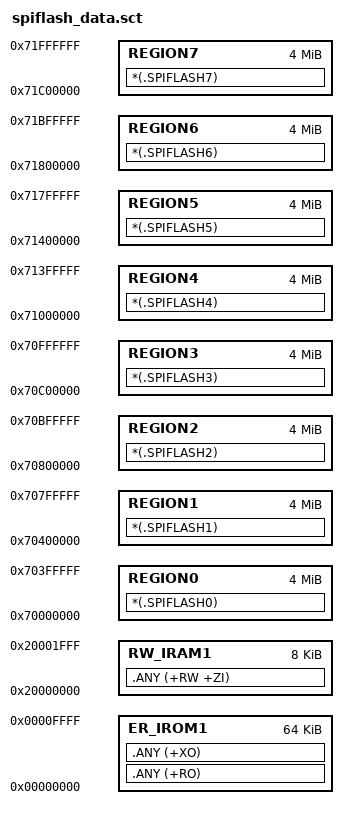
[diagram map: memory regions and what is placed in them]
; *************************************************************
; *** Scatter-Loading Description File generated by uVision ***
; *************************************************************
LR_IROM1 0x00000000 0x00010000  {    ; load region size_region
  ER_IROM1 0x00000000 0x00010000  {  ; load address = execution address
   .ANY (+RO)
   .ANY (+XO)
  }
  RW_IRAM1 0x20000000 0x00002000  {  ; RW data
   .ANY (+RW +ZI)
  }
}

LR_SPIFLASH 0x70000000 0x02000000  {      ; load region size_region
  REGION0 0x70000000 0x00400000  {
    *(.SPIFLASH0)
  }
  REGION1 0x70400000 0x00400000  {
    *(.SPIFLASH1)
  }
  REGION2 0x70800000 0x00400000  {
    *(.SPIFLASH2)
  }
  REGION3 0x70C00000 0x00400000  {
    *(.SPIFLASH3)
  }
  REGION4 0x71000000 0x00400000  {
    *(.SPIFLASH4)
  }
  REGION5 0x71400000 0x00400000  {
    *(.SPIFLASH5)
  }
  REGION6 0x71800000 0x00400000  {
    *(.SPIFLASH6)
  }
  REGION7 0x71C00000 0x00400000  {
    *(.SPIFLASH7)
  }
}

